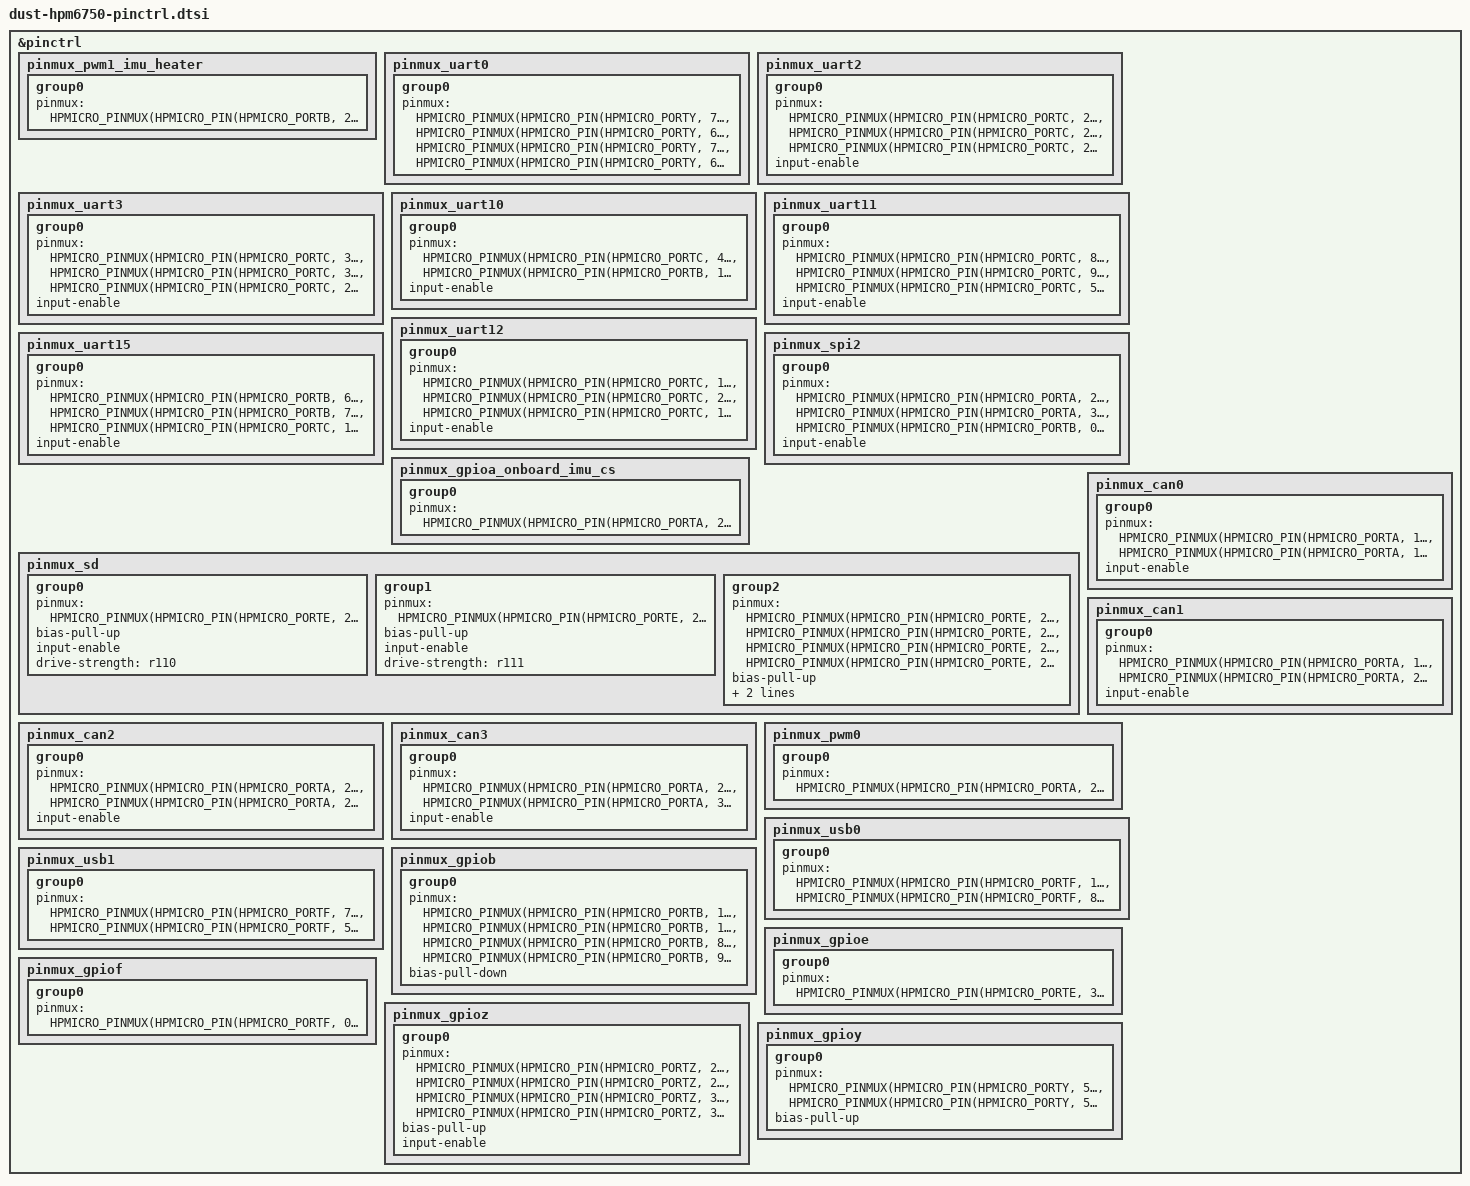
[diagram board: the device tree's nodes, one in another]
/*
 * Copyright 2024-2025 HPMicro
 * SPDX-License-Identifier: Apache-2.0
 */

#include "dt-bindings/pinctrl/hpmicro-pinctrl-common.h"

&pinctrl {
	pinmux_pwm1_imu_heater: pinmux_pwm1_imu_heater {
		group0 {
			pinmux = <HPMICRO_PINMUX(HPMICRO_PIN(HPMICRO_PORTB, 2),
						 IOC_TYPE_IOC, 0, 16)>;
		};
	};

	pinmux_uart0: pinmux_uart0 {
		group0 {
			pinmux = <HPMICRO_PINMUX(HPMICRO_PIN(HPMICRO_PORTY, 7), IOC_TYPE_IOC, 0, 2)>,
					 <HPMICRO_PINMUX(HPMICRO_PIN(HPMICRO_PORTY, 6), IOC_TYPE_IOC, 0, 2)>,
					 <HPMICRO_PINMUX(HPMICRO_PIN(HPMICRO_PORTY, 7), IOC_TYPE_PIOC, 0, 3)>,
					 <HPMICRO_PINMUX(HPMICRO_PIN(HPMICRO_PORTY, 6), IOC_TYPE_PIOC, 0, 3)>;
		};
	};

	pinmux_uart2: pinmux_uart2 {
		group0 {
			pinmux = <HPMICRO_PINMUX(HPMICRO_PIN(HPMICRO_PORTC, 23), IOC_TYPE_IOC, 0, 2)>,
					 <HPMICRO_PINMUX(HPMICRO_PIN(HPMICRO_PORTC, 24), IOC_TYPE_IOC, 0, 2)>,
					 <HPMICRO_PINMUX(HPMICRO_PIN(HPMICRO_PORTC, 22), IOC_TYPE_IOC, 0, 16)>;
			input-enable;
		};
	};

	pinmux_uart3: pinmux_uart3 {
		group0 {
			pinmux = <HPMICRO_PINMUX(HPMICRO_PIN(HPMICRO_PORTC, 30), IOC_TYPE_IOC, 0, 2)>,
					 <HPMICRO_PINMUX(HPMICRO_PIN(HPMICRO_PORTC, 31), IOC_TYPE_IOC, 0, 2)>,
					 <HPMICRO_PINMUX(HPMICRO_PIN(HPMICRO_PORTC, 25), IOC_TYPE_IOC, 0, 16)>;
			input-enable;
		};
	};

	pinmux_uart10: pinmux_uart10 {
		group0 {
			pinmux = <HPMICRO_PINMUX(HPMICRO_PIN(HPMICRO_PORTC, 4), IOC_TYPE_IOC, 0, 2)>,
					 <HPMICRO_PINMUX(HPMICRO_PIN(HPMICRO_PORTB, 13), IOC_TYPE_IOC, 0, 16)>;
			input-enable;
		};
	};

	pinmux_uart11: pinmux_uart11 {
		group0 {
			pinmux = <HPMICRO_PINMUX(HPMICRO_PIN(HPMICRO_PORTC, 8), IOC_TYPE_IOC, 0, 2)>,
					 <HPMICRO_PINMUX(HPMICRO_PIN(HPMICRO_PORTC, 9), IOC_TYPE_IOC, 0, 2)>,
					 <HPMICRO_PINMUX(HPMICRO_PIN(HPMICRO_PORTC, 5), IOC_TYPE_IOC, 0, 16)>;
			input-enable;
		};
	};

	pinmux_uart12: pinmux_uart12 {
		group0 {
			pinmux = <HPMICRO_PINMUX(HPMICRO_PIN(HPMICRO_PORTC, 15), IOC_TYPE_IOC, 0, 2)>,
					 <HPMICRO_PINMUX(HPMICRO_PIN(HPMICRO_PORTC, 20), IOC_TYPE_IOC, 0, 2)>,
					 <HPMICRO_PINMUX(HPMICRO_PIN(HPMICRO_PORTC, 19), IOC_TYPE_IOC, 0, 16)>;
			input-enable;
		};
	};

	pinmux_uart15: pinmux_uart15 {
		group0 {
			pinmux = <HPMICRO_PINMUX(HPMICRO_PIN(HPMICRO_PORTB, 6), IOC_TYPE_IOC, 0, 2)>,
					 <HPMICRO_PINMUX(HPMICRO_PIN(HPMICRO_PORTB, 7), IOC_TYPE_IOC, 0, 2)>,
					 <HPMICRO_PINMUX(HPMICRO_PIN(HPMICRO_PORTC, 10), IOC_TYPE_IOC, 0, 16)>;
			input-enable;
		};
	};

	pinmux_spi2: pinmux_spi2 {
		group0 {
			/* PA26 is GPIO CS; SPI2 keeps SCLK/MOSI/MISO only. */
			pinmux = <HPMICRO_PINMUX(HPMICRO_PIN(HPMICRO_PORTA, 27), IOC_TYPE_IOC, 0, 5)>,
					 <HPMICRO_PINMUX(HPMICRO_PIN(HPMICRO_PORTA, 31), IOC_TYPE_IOC, 0, 5)>,
					 <HPMICRO_PINMUX(HPMICRO_PIN(HPMICRO_PORTB, 0), IOC_TYPE_IOC, 0, 5)>;
			input-enable;
		};
	};

	pinmux_gpioa_onboard_imu_cs: pinmux_gpioa_onboard_imu_cs {
		group0 {
			pinmux = <HPMICRO_PINMUX(HPMICRO_PIN(HPMICRO_PORTA, 26), IOC_TYPE_IOC, 0, 0)>;
		};
	};

	pinmux_sd: pinmux_sd {
		group0 {
			/* SDC0_CMD: PE22 */
			pinmux = <HPMICRO_PINMUX(HPMICRO_PIN(HPMICRO_PORTE, 22), IOC_TYPE_IOC, 0, 17)>;
			bias-pull-up;
			input-enable;
			drive-strength = "r110";
		};
		group1 {
			/* SDC0_CLK: PE27 */
			pinmux = <HPMICRO_PINMUX(HPMICRO_PIN(HPMICRO_PORTE, 27), IOC_TYPE_IOC, 0, 17)>;
			bias-pull-up;
			input-enable;
			drive-strength = "r111";
		};
		group2 {
			/* SDC0_D0..D3: PE26, PE21, PE28, PE23 */
			pinmux = <HPMICRO_PINMUX(HPMICRO_PIN(HPMICRO_PORTE, 26), IOC_TYPE_IOC, 0, 17)>,
				 <HPMICRO_PINMUX(HPMICRO_PIN(HPMICRO_PORTE, 21), IOC_TYPE_IOC, 0, 17)>,
				 <HPMICRO_PINMUX(HPMICRO_PIN(HPMICRO_PORTE, 28), IOC_TYPE_IOC, 0, 17)>,
				 <HPMICRO_PINMUX(HPMICRO_PIN(HPMICRO_PORTE, 23), IOC_TYPE_IOC, 0, 17)>;
			bias-pull-up;
			input-enable;
			drive-strength = "r111";
		};
	};

	pinmux_can0: pinmux_can0 {
		group0 {
			pinmux = <HPMICRO_PINMUX(HPMICRO_PIN(HPMICRO_PORTA, 16), IOC_TYPE_IOC, 0, 7)>,
					<HPMICRO_PINMUX(HPMICRO_PIN(HPMICRO_PORTA, 17), IOC_TYPE_IOC, 0, 7)>;
			input-enable;
		};
	};

	pinmux_can1: pinmux_can1 {
		group0 {
			/* CAN1: PA19 = RX, PA20 = TX. */
			pinmux = <HPMICRO_PINMUX(HPMICRO_PIN(HPMICRO_PORTA, 19), IOC_TYPE_IOC, 0, 7)>,
					<HPMICRO_PINMUX(HPMICRO_PIN(HPMICRO_PORTA, 20), IOC_TYPE_IOC, 0, 7)>;
			input-enable;
		};
	};

	pinmux_can2: pinmux_can2 {
		group0 {
			pinmux = <HPMICRO_PINMUX(HPMICRO_PIN(HPMICRO_PORTA, 24), IOC_TYPE_IOC, 0, 7)>,
					<HPMICRO_PINMUX(HPMICRO_PIN(HPMICRO_PORTA, 25), IOC_TYPE_IOC, 0, 7)>;
			input-enable;
		};
	};

	pinmux_can3: pinmux_can3 {
		group0 {
			pinmux = <HPMICRO_PINMUX(HPMICRO_PIN(HPMICRO_PORTA, 29), IOC_TYPE_IOC, 0, 7)>,
					<HPMICRO_PINMUX(HPMICRO_PIN(HPMICRO_PORTA, 30), IOC_TYPE_IOC, 0, 7)>;
			input-enable;
		};
	};

	pinmux_pwm0: pinmux_pwm0 {
		group0 {
			pinmux = <HPMICRO_PINMUX(HPMICRO_PIN(HPMICRO_PORTA, 22), IOC_TYPE_IOC, 0, 16)>;
		};
	};

	pinmux_usb0: pinmux_usb0 {
		group0 {
			pinmux = <HPMICRO_PINMUX(HPMICRO_PIN(HPMICRO_PORTF, 10), IOC_TYPE_IOC, 0, 24)>,
					 <HPMICRO_PINMUX(HPMICRO_PIN(HPMICRO_PORTF,  8), IOC_TYPE_IOC, 0, 24)>;
		};
	};

	pinmux_usb1: pinmux_usb1 {
		group0 {
			pinmux = <HPMICRO_PINMUX(HPMICRO_PIN(HPMICRO_PORTF, 7), IOC_TYPE_IOC, 0, 24)>,
					 <HPMICRO_PINMUX(HPMICRO_PIN(HPMICRO_PORTF, 5), IOC_TYPE_IOC, 0, 24)>;
		};
	};

	pinmux_gpiob: pinmux_gpiob {
		group0 {
			pinmux = <HPMICRO_PINMUX(HPMICRO_PIN(HPMICRO_PORTB, 11), IOC_TYPE_IOC, 0, 0)>,
					 <HPMICRO_PINMUX(HPMICRO_PIN(HPMICRO_PORTB, 12), IOC_TYPE_IOC, 0, 0)>,
					 <HPMICRO_PINMUX(HPMICRO_PIN(HPMICRO_PORTB, 8), IOC_TYPE_IOC, 0, 0)>,
					 <HPMICRO_PINMUX(HPMICRO_PIN(HPMICRO_PORTB, 9), IOC_TYPE_IOC, 0, 0)>;
			bias-pull-down;
		};
	};

	pinmux_gpioe: pinmux_gpioe {
		group0 {
			pinmux = <HPMICRO_PINMUX(HPMICRO_PIN(HPMICRO_PORTE, 31), IOC_TYPE_IOC, 0, 0)>;
		};
	};

	pinmux_gpiof: pinmux_gpiof {
		group0 {
			pinmux = <HPMICRO_PINMUX(HPMICRO_PIN(HPMICRO_PORTF, 0), IOC_TYPE_IOC, 0, 0)>;
		};
	};

	pinmux_gpioz: pinmux_gpioz {
		group0 {
			pinmux = <HPMICRO_PINMUX(HPMICRO_PIN(HPMICRO_PORTZ, 2), IOC_TYPE_IOC, 0, 0)>,
					 <HPMICRO_PINMUX(HPMICRO_PIN(HPMICRO_PORTZ, 2), IOC_TYPE_BIOC, 0, 3)>,
					 <HPMICRO_PINMUX(HPMICRO_PIN(HPMICRO_PORTZ, 3), IOC_TYPE_IOC, 0, 0)>,
					 <HPMICRO_PINMUX(HPMICRO_PIN(HPMICRO_PORTZ, 3), IOC_TYPE_BIOC, 0, 3)>;
			bias-pull-up;
			input-enable;
		};
	};

	pinmux_gpioy: pinmux_gpioy {
		group0 {
			pinmux = <HPMICRO_PINMUX(HPMICRO_PIN(HPMICRO_PORTY, 5), IOC_TYPE_IOC, 0, 0)>,
					 <HPMICRO_PINMUX(HPMICRO_PIN(HPMICRO_PORTY, 5), IOC_TYPE_BIOC, 0, 3)>;
			bias-pull-up;
		};
	};


};
